# STM32C562 register map
File version: 1.0.0
CPU: CM33 r0p4, little endian, MPU, FPU, 4 interrupt priority bits
Registers are 32-bit, read-write, reset 0x0 unless marked. A register's access mark holds for its fields unless they carry their own. Offsets are from the block's base; [hi:lo] are bit positions.

## SBS — SBS address block description
Base 0x44000400
0x10 SBS_HDPLCR reset 0xB4 — SBS temporal isolation control register
  [7:0] INCR_HDPL — increment HDPL value
    180=no increment; 106=recommended value to increment HDPL level by one
0x14 SBS_HDPLSR ro reset not defined — SBS temporal isolation status register
  [7:0] HDPL — temporal isolation level
    81=HDPL1, hide protection level to be used to execute and protect an immutable root of trust (IROT) stage; 138=HDPL2, hide protection level to be used to execute and protect an updatable Root of Trust (UROT) stage; 111=HDPL3, hide protection level to be used to execute the application
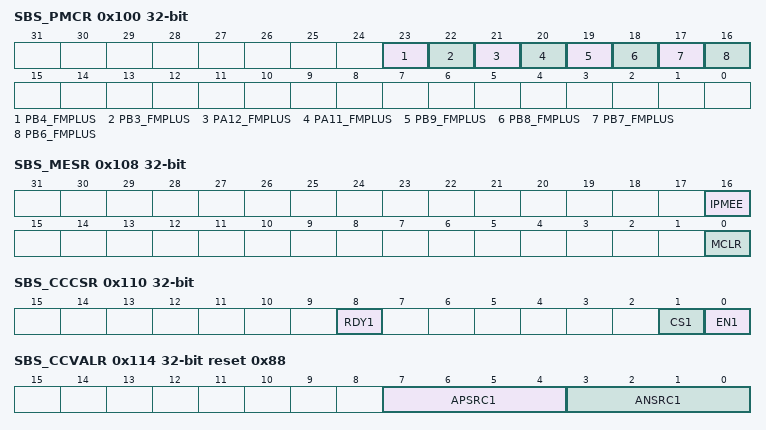
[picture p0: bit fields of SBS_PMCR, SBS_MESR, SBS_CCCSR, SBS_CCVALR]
0x100 SBS_PMCR — SBS product mode and configuration register
  [23] PB4_FMPLUS — Fast-mode Plus command on PB(4)
    0=Fast-mode Plus mode on PB(4) is disabled; 1=Fast-mode Plus mode on PB(4) is enabled
  [22] PB3_FMPLUS — Fast-mode Plus command on PB(3)
    0=Fast-mode Plus mode on PB(3) is disabled; 1=Fast-mode Plus mode on PB(3) is enabled
  [21] PA12_FMPLUS — Fast-mode Plus command on PA(12)
    0=Fast-mode Plus mode on PA(12) is disabled; 1=Fast-mode Plus mode on PA(12) is enabled
  [20] PA11_FMPLUS — Fast-mode Plus command on PA(11)
    0=Fast-mode Plus mode on PA(11) is disabled; 1=Fast-mode Plus mode on PA(11) is enabled
  [19] PB9_FMPLUS — Fast-mode Plus command on PB(9)
    0=Fast-mode Plus mode on PB(9) is disabled; 1=Fast-mode Plus mode on PB(9) is enabled
  [18] PB8_FMPLUS — Fast-mode Plus command on PB(8)
    0=Fast-mode Plus mode on PB(8) is disabled; 1=Fast-mode Plus mode on PB(8) is enabled
  [17] PB7_FMPLUS — Fast-mode Plus command on PB(7)
    0=Fast-mode Plus mode on PB(7) is disabled; 1=Fast mode plus mode on PB(7) is enabled
  [16] PB6_FMPLUS — Fast-mode Plus command on PB(6)
    0=Fast-mode Plus mode on PB(6) is disabled; 1=Fast-mode Plus mode on PB(6) is enabled
0x104 SBS_FPUIMR reset 0x1F — SBS FPU interrupt mask register
  [5:0] FPU_IE — FPU interrupt enable
0x108 SBS_MESR (reset mask 0xFFF0FFF0) — SBS memory erase status register
  [16] IPMEE — ICACHE erase status
    0=ICACHE erase ongoing; 1=ICACHE erase ended
  [0] MCLR — Device memories erase status
    0=memory erase ongoing if not yet cleared by software; 1=memory erase done
0x110 SBS_CCCSR — SBS compensation cell for I/Os control and status register
  [8] RDY1 ro — VDDIO compensation cell ready flag
    0=VDDIO compensation cell not ready; 1=VDDIO compensation cell ready (code value provided by the cell can be used)
  [1] CS1 — code selection for VDDIO power rail (reset value set to 1)
    0=Code from the cell (available in the SBS_CCVR); 1=Code from SBS_CCCR
  [0] EN1 — enable compensation cell for VDDIO power rail
    0=I/O compensation cell disabled; 1=I/O compensation cell enabled
0x114 SBS_CCVALR ro reset 0x88 — SBS compensation cell for I/Os value register
  [7:4] APSRC1 — compensation value for the PMOS transistor
  [3:0] ANSRC1 — compensation value for the NMOS transistor
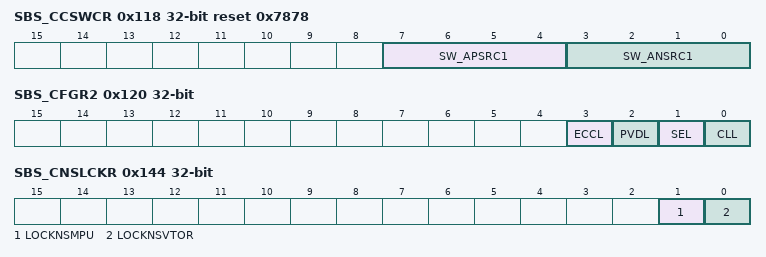
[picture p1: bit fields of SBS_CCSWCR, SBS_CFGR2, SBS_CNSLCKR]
0x118 SBS_CCSWCR reset 0x7878 — SBS compensation cell for I/Os software code register
  [7:4] SW_APSRC1 — PMOS compensation code for the VDD power rails
  [3:0] SW_ANSRC1 — NMOS compensation code for VDD power rails
0x120 SBS_CFGR2 — SBS Class B register
  [3] ECCL — ECC lock
    0=double ECC error flag disconnected to timer break inputs; 1=double ECC error flag connected to timer break inputs
  [2] PVDL — PVD lock
    0=PVD interrupt disconnected from timer break inputs; 1=PVD interrupt is connected to timer break inputs
  [1] SEL — SRAM ECC error lock
    0=SRAM double ECC error flag disconnected from timer break inputs; 1=SRAM double ECC error flag connected to timer break inputs
  [0] CLL — core lockup lock
    0=lockup output disconnected from timer break inputs; 1=lockup output connected to timer break inputs
0x144 SBS_CNSLCKR — SBS CPU lock register
  [1] LOCKNSMPU — MPU register lock
    0=MPU registers write enabled; 1=MPU registers write disabled
  [0] LOCKNSVTOR — VTOR_NS register lock
    0=VTOR_NS register write enabled; 1=VTOR_NS register write disabled
0x14C SBS_ECCNMIR — SBS flift ECC NMI mask register
  [0] ECCNMI_MASK_EN — NMI behavior setup when a double ECC error occurs on FLITF data part
    0=NMI generated if a double ECC error in the FLITF data part; 1=NMI not generated if a double ECC error in the FLITF data part
